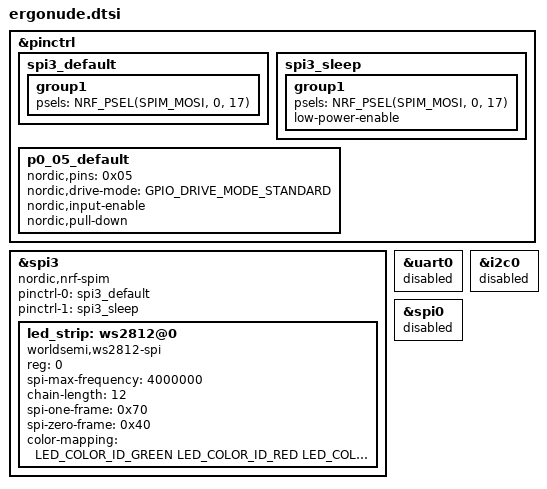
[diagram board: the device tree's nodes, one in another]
#include <dt-bindings/gpio/gpio.h>
#include <dt-bindings/pinctrl/nrf-pinctrl.h>

&pinctrl {
    spi3_default: spi3_default {
        group1 {
            psels = <NRF_PSEL(SPIM_MOSI, 0, 17)>;
        };
    };
    spi3_sleep: spi3_sleep {
        group1 {
            psels = <NRF_PSEL(SPIM_MOSI, 0, 17)>;
            low-power-enable;
        };
    };
};

&spi3 {
    compatible = "nordic,nrf-spim";
    status = "okay";
    pinctrl-0 = <&spi3_default>;
    pinctrl-1 = <&spi3_sleep>;
    pinctrl-names = "default", "sleep";

    led_strip: ws2812@0 {
        compatible = "worldsemi,ws2812-spi";
        reg = <0>;
        spi-max-frequency = <4000000>;
        chain-length = <12>;
        spi-one-frame = <0x70>;
        spi-zero-frame = <0x40>;
        color-mapping = <LED_COLOR_ID_GREEN LED_COLOR_ID_RED LED_COLOR_ID_BLUE>;
    };
};
/ {
    // 禁用可能使用P0.05的外设
    fragment@0 {
        target = <&uart0>;
        __overlay__ {
            status = "disabled";
        };
    };

    fragment@1 {
        target = <&i2c0>;
        __overlay__ {
            status = "disabled";
        };
    };

    fragment@2 {
        target = <&spi0>;
        __overlay__ {
            status = "disabled";
        };
    };

    // 确保P0.05配置为GPIO
    fragment@3 {
        target = <&pinctrl>;
        __overlay__ {
            p0_05_default: p0_05_default {
                nordic,pins = <0x05>;
                nordic,drive-mode = <GPIO_DRIVE_MODE_STANDARD>;
                nordic,input-enable;
                nordic,pull-down;
            };
        };
    };
};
